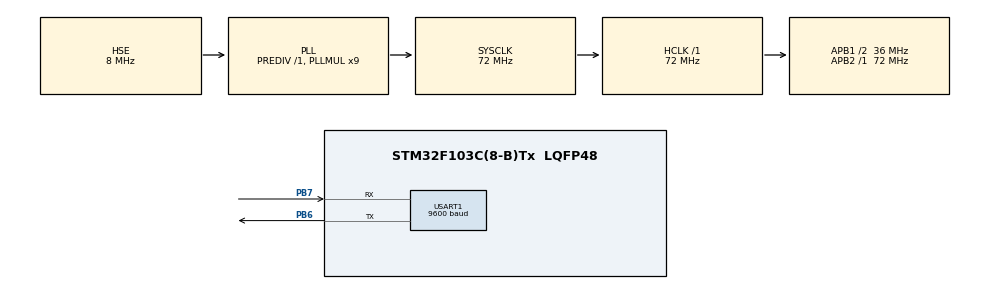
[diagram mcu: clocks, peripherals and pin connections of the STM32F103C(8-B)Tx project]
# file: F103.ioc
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Mcu.Family=STM32F1
Mcu.Name=STM32F103C(8-B)Tx
Mcu.Package=LQFP48
NVIC.PriorityGroup=NVIC_PRIORITYGROUP_4
NVIC.USART1_IRQn=true\:0\:0\:false\:false\:true\:true\:true
PA13.Mode=Serial_Wire
PA13.Signal=SYS_JTMS-SWDIO
PA14.Mode=Serial_Wire
PA14.Signal=SYS_JTCK-SWCLK
PB6.Mode=Asynchronous
PB6.Signal=USART1_TX
PB7.Mode=Asynchronous
PB7.Signal=USART1_RX
PD0-OSC_IN.Mode=HSE-External-Oscillator
PD0-OSC_IN.Signal=RCC_OSC_IN
PD1-OSC_OUT.Mode=HSE-External-Oscillator
PD1-OSC_OUT.Signal=RCC_OSC_OUT
ProjectManager.HeapSize=0x200
ProjectManager.StackSize=0x400
ProjectManager.TargetToolchain=MDK-ARM V5.27
RCC.AHBFreq_Value=72000000
RCC.APB1CLKDivider=RCC_HCLK_DIV2
RCC.APB1Freq_Value=36000000
RCC.APB1TimFreq_Value=72000000
RCC.APB2Freq_Value=72000000
RCC.APB2TimFreq_Value=72000000
RCC.HCLKFreq_Value=72000000
RCC.PLLMUL=RCC_PLL_MUL9
RCC.PLLSourceVirtual=RCC_PLLSOURCE_HSE
RCC.SYSCLKFreq_VALUE=72000000
RCC.SYSCLKSource=RCC_SYSCLKSOURCE_PLLCLK
RCC.USBFreq_Value=72000000
USART1.BaudRate=9600
USART1.VirtualMode=VM_ASYNC
board=custom

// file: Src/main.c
/* USER CODE BEGIN Header */
/***************************************************************************//**
  文件: main.c
  作者: Zhengyu https://gzwelink.taobao.com
  版本: V1.0.0
  时间: 20200401
	平台:MINI-F103C8T6

*******************************************************************************/
/* USER CODE END Header */
#include "main.h"
#include "usart.h"
#include "gpio.h"
#include "string.h"
#include "JDY31.h"
/* USER CODE BEGIN Includes */
extern void JDY31_BaudRateSet(void);
extern void  JDY31_PINRead ( void );

/* USER CODE END Includes */

/* USER CODE BEGIN PM */
#ifdef __GNUC__
  /* With GCC/RAISONANCE, small printf (option LD Linker->Libraries->Small printf
     set to 'Yes') calls __io_putchar() */
  #define PUTCHAR_PROTOTYPE int __io_putchar(int ch)
#else
  #define PUTCHAR_PROTOTYPE int fputc(int ch, FILE *f)
#endif /* __GNUC__ */
/**
  * @brief  Retargets the C library printf function to the USART.
  * @param  None
  * @retval None
  */
PUTCHAR_PROTOTYPE
{
  /* Place your implementation of fputc here */
  /* e.g. write a character to the EVAL_COM1 and Loop until the end of transmission */
//  HAL_UART_Transmit(&huart2, (uint8_t *)&ch, 1, 0xFFFF);
  return ch;
}
/* USER CODE END PM */

void SystemClock_Config(void);

/* USER CODE BEGIN 0 */
volatile uint8_t UartRxData;
uint8_t UartTxbuf[1000]={1,2,3,4,5,6,7,8,9,10};
uint8_t UartRxbuf[1024],UartIntRxbuf[1024];
uint16_t UartRxIndex=0,UartRxFlag,UartRxLen=0,UartRxTimer,UartRxOKFlag,UartIntRxLen;

//串口清除
uint8_t UartRecv_Clear(void)
{
	UartRxOKFlag=0;
	UartRxLen=0;
	UartIntRxLen=0;
	UartRxIndex=0;
	return 1;
}

uint8_t Blue_ConnectFlag;//1:连接上，0：断开
//接收标志函数，返回0说明没收据接收，返回1说明有数据收到
uint8_t Uart_RecvFlag(void)
{
		if(UartRxOKFlag==0x55)
		{
			UartRxOKFlag=0;
			UartRxLen=UartIntRxLen;
			memcpy(UartRxbuf,UartIntRxbuf,UartIntRxLen);//把缓冲区的数据，放入需要解析的数组
			UartIntRxLen=0;

			if(Blue_ConnectFlag==0)//没连接上，才判断是否有连接信号
			{
				Blue_ConnectFlag = strstr ((const char*)UartRxbuf, "CONNECTED" ) ? 1 : 0;//说明蓝牙跟手机连上
				if(Blue_ConnectFlag)//如果刚连接上，先发送一个HELLOWORLD
				{
					UartRxLen=0;
					HAL_UART_Transmit(&huart1, "HELLOWORLD\r\n", 12,100);

				}
			}

			if(Blue_ConnectFlag==1)//连接上了，才判断断开
			{
			Blue_ConnectFlag = strstr ((const char*)UartRxbuf, "+DISC:SUCCESS" ) ? 0 : 1;//说明蓝牙跟手机断开

			}
			return 1;
		}
		return 0;
}
//串口2在1字节接收完成回调函数
void HAL_UART_RxCpltCallback(UART_HandleTypeDef *huart)
{

	if(huart==&huart1)//判断是否串口1
	{
		UartRxFlag=0x55;//接收标志置位
		UartIntRxbuf[UartRxIndex]=UartRxData;//数据写入缓冲区
		UartRxIndex++;//记载数目加1
		if(UartRxIndex>=1024)//缓冲区是1024字节，如果存满，归零
		{
			UartRxIndex=0;
		}
		HAL_UART_Receive_IT(&huart1,(unsigned char*)&UartRxData,1);//继续接收下一字节
 }

}

//1ms调用一次，用来判断是否收完一帧
void UART_RecvDealwith(void)
{
	if(UartRxFlag==0x55)
	{
		if(UartIntRxLen<UartRxIndex)//UartIntRxLen小于UartRxIndex，说明有收到新的数据，把接收长度增加
		{
		UartIntRxLen=UartRxIndex;
		}else
		{
			UartRxTimer++;
			if(UartRxTimer>=50)//50ms,等待，没收到新数据，说明已经收完一帧
			{
				UartRxTimer=0;
				UartRxFlag=0;
				UartRxOKFlag=0x55;
				UartRxIndex=0;
			}
		}
	}
}
/* USER CODE END 0 */

int main(void)
{

  /* MCU Configuration--------------------------------------------------------*/

  /* Reset of all peripherals, Initializes the Flash interface and the Systick. */
  HAL_Init();

  /* Configure the system clock */
  SystemClock_Config();//8M外部晶振，72M系统主频

  /* Initialize all configured peripherals */
  MX_GPIO_Init();
  MX_USART1_UART_Init();//串口1配置，PB6 发送，PB7 接收
  /* USER CODE BEGIN 2 */
	HAL_UART_Receive_IT(&huart1, (uint8_t *)&UartRxData, 1);//接收中断使能
  /* USER CODE END 2 */

  /* Infinite loop */
  /* USER CODE BEGIN WHILE */

	JDY31_AT_Test();//蓝牙AT指令测试
	JDY31_BaudRateSet();//波特率设置，9600
	JDY31_PINRead();//读PIN
  while (1)
  {
    /* USER CODE END WHILE */

    /* USER CODE BEGIN 3 */

		if(Uart_RecvFlag()==1)//判断串口是否有数据收到
		{
				if(Blue_ConnectFlag)//如果蓝牙已经连接上，把收到的数据发出去
				{
					if(UartRxLen)//判断收到的数据长度有效
					{
						HAL_UART_Transmit(&huart1,UartRxbuf, UartRxLen,100);//发送数据
					}
				}
		}

  }
  /* USER CODE END 3 */
}

void SystemClock_Config(void)
{
  RCC_OscInitTypeDef RCC_OscInitStruct = {0};
  RCC_ClkInitTypeDef RCC_ClkInitStruct = {0};

  /** Initializes the RCC Oscillators according to the specified parameters
  * in the RCC_OscInitTypeDef structure.
  */
  RCC_OscInitStruct.OscillatorType = RCC_OSCILLATORTYPE_HSE;
  RCC_OscInitStruct.HSEState = RCC_HSE_ON;
  RCC_OscInitStruct.HSEPredivValue = RCC_HSE_PREDIV_DIV1;
  RCC_OscInitStruct.HSIState = RCC_HSI_ON;
  RCC_OscInitStruct.PLL.PLLState = RCC_PLL_ON;
  RCC_OscInitStruct.PLL.PLLSource = RCC_PLLSOURCE_HSE;
  RCC_OscInitStruct.PLL.PLLMUL = RCC_PLL_MUL9;
  if (HAL_RCC_OscConfig(&RCC_OscInitStruct) != HAL_OK)
  {
    Error_Handler();
  }
  /** Initializes the CPU, AHB and APB buses clocks
  */
  RCC_ClkInitStruct.ClockType = RCC_CLOCKTYPE_HCLK|RCC_CLOCKTYPE_SYSCLK
                              |RCC_CLOCKTYPE_PCLK1|RCC_CLOCKTYPE_PCLK2;
  RCC_ClkInitStruct.SYSCLKSource = RCC_SYSCLKSOURCE_PLLCLK;
  RCC_ClkInitStruct.AHBCLKDivider = RCC_SYSCLK_DIV1;
  RCC_ClkInitStruct.APB1CLKDivider = RCC_HCLK_DIV2;
  RCC_ClkInitStruct.APB2CLKDivider = RCC_HCLK_DIV1;

  if (HAL_RCC_ClockConfig(&RCC_ClkInitStruct, FLASH_LATENCY_2) != HAL_OK)
  {
    Error_Handler();
  }
}

void Error_Handler(void)
{
}

/************************ (C) COPYRIGHT STMicroelectronics *****END OF FILE****/
